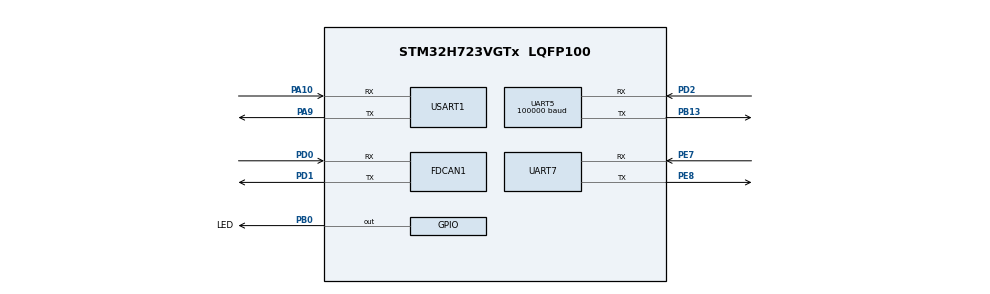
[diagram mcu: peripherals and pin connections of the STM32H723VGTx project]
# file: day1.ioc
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CORTEX_M7.default_mode_Activation=1
Dma.Request0=UART7_TX
Dma.Request1=UART5_RX
Dma.Request2=USART1_TX
Dma.UART5_RX.1.Direction=DMA_PERIPH_TO_MEMORY
Dma.UART5_RX.1.EventEnable=DISABLE
Dma.UART5_RX.1.FIFOMode=DMA_FIFOMODE_DISABLE
Dma.UART5_RX.1.Instance=DMA1_Stream1
Dma.UART5_RX.1.MemDataAlignment=DMA_MDATAALIGN_BYTE
Dma.UART5_RX.1.MemInc=DMA_MINC_ENABLE
Dma.UART5_RX.1.Mode=DMA_NORMAL
Dma.UART5_RX.1.PeriphDataAlignment=DMA_PDATAALIGN_BYTE
Dma.UART5_RX.1.PeriphInc=DMA_PINC_DISABLE
Dma.UART5_RX.1.Polarity=HAL_DMAMUX_REQ_GEN_RISING
Dma.UART5_RX.1.Priority=DMA_PRIORITY_HIGH
Dma.UART5_RX.1.RequestNumber=1
Dma.UART5_RX.1.SignalID=NONE
Dma.UART5_RX.1.SyncEnable=DISABLE
Dma.UART5_RX.1.SyncPolarity=HAL_DMAMUX_SYNC_NO_EVENT
Dma.UART5_RX.1.SyncRequestNumber=1
Dma.UART5_RX.1.SyncSignalID=NONE
Dma.UART7_TX.0.Direction=DMA_MEMORY_TO_PERIPH
Dma.UART7_TX.0.EventEnable=DISABLE
Dma.UART7_TX.0.FIFOMode=DMA_FIFOMODE_DISABLE
Dma.UART7_TX.0.Instance=DMA1_Stream0
Dma.UART7_TX.0.MemDataAlignment=DMA_MDATAALIGN_BYTE
Dma.UART7_TX.0.MemInc=DMA_MINC_ENABLE
Dma.UART7_TX.0.Mode=DMA_NORMAL
Dma.UART7_TX.0.PeriphDataAlignment=DMA_PDATAALIGN_BYTE
Dma.UART7_TX.0.PeriphInc=DMA_PINC_DISABLE
Dma.UART7_TX.0.Polarity=HAL_DMAMUX_REQ_GEN_RISING
Dma.UART7_TX.0.Priority=DMA_PRIORITY_LOW
Dma.UART7_TX.0.RequestNumber=1
Dma.UART7_TX.0.SignalID=NONE
Dma.UART7_TX.0.SyncEnable=DISABLE
Dma.UART7_TX.0.SyncPolarity=HAL_DMAMUX_SYNC_NO_EVENT
Dma.UART7_TX.0.SyncRequestNumber=1
Dma.UART7_TX.0.SyncSignalID=NONE
Dma.USART1_TX.2.Direction=DMA_MEMORY_TO_PERIPH
Dma.USART1_TX.2.EventEnable=DISABLE
Dma.USART1_TX.2.FIFOMode=DMA_FIFOMODE_DISABLE
Dma.USART1_TX.2.Instance=DMA1_Stream2
Dma.USART1_TX.2.MemDataAlignment=DMA_MDATAALIGN_BYTE
Dma.USART1_TX.2.MemInc=DMA_MINC_ENABLE
Dma.USART1_TX.2.Mode=DMA_NORMAL
Dma.USART1_TX.2.PeriphDataAlignment=DMA_PDATAALIGN_BYTE
Dma.USART1_TX.2.PeriphInc=DMA_PINC_DISABLE
Dma.USART1_TX.2.Polarity=HAL_DMAMUX_REQ_GEN_RISING
Dma.USART1_TX.2.Priority=DMA_PRIORITY_LOW
Dma.USART1_TX.2.RequestNumber=1
Dma.USART1_TX.2.SignalID=NONE
Dma.USART1_TX.2.SyncEnable=DISABLE
Dma.USART1_TX.2.SyncPolarity=HAL_DMAMUX_SYNC_NO_EVENT
Dma.USART1_TX.2.SyncRequestNumber=1
Dma.USART1_TX.2.SyncSignalID=NONE
FDCAN1.CalculateBaudRateNominal=999999
FDCAN1.CalculateTimeBitNominal=1000
FDCAN1.CalculateTimeQuantumNominal=16.666666666666668
FDCAN1.DataPrescaler=2
FDCAN1.DataSyncJumpWidth=6
FDCAN1.DataTimeSeg1=17
FDCAN1.DataTimeSeg2=6
FDCAN1.ExtFiltersNbr=4
FDCAN1.Mode=FDCAN_MODE_NORMAL
FDCAN1.NominalPrescaler=2
FDCAN1.NominalSyncJumpWidth=15
FDCAN1.NominalTimeSeg1=44
FDCAN1.NominalTimeSeg2=15
FDCAN1.RxBuffersNbr=8
FDCAN1.RxFifo0ElmtsNbr=8
FDCAN1.RxFifo1ElmtsNbr=8
FDCAN1.StdFiltersNbr=4
FDCAN1.TxBuffersNbr=8
FDCAN1.TxEventsNbr=8
FDCAN1.TxFifoQueueElmtsNbr=8
FREERTOS.Tasks01=defaultTask,24,128,StartDefaultTask,Default,NULL,Dynamic,NULL,NULL
Mcu.Family=STM32H7
Mcu.Name=STM32H723VGTx
Mcu.Package=LQFP100
NVIC.DMA1_Stream0_IRQn=true\:5\:0\:false\:false\:true\:true\:false\:true\:true
NVIC.DMA1_Stream1_IRQn=true\:5\:0\:false\:false\:true\:true\:false\:true\:true
NVIC.DMA1_Stream2_IRQn=true\:5\:0\:false\:false\:true\:true\:false\:true\:true
NVIC.FDCAN1_IT0_IRQn=true\:5\:0\:false\:false\:true\:true\:true\:true\:true
NVIC.FDCAN1_IT1_IRQn=true\:5\:0\:false\:false\:true\:true\:true\:true\:true
NVIC.PriorityGroup=NVIC_PRIORITYGROUP_4
NVIC.TIM6_DAC_IRQn=true\:5\:0\:false\:false\:true\:true\:true\:true\:true
NVIC.UART5_IRQn=true\:5\:0\:false\:false\:true\:true\:true\:true\:true
NVIC.UART7_IRQn=true\:5\:0\:false\:false\:true\:true\:true\:true\:true
NVIC.USART1_IRQn=true\:5\:0\:false\:false\:true\:true\:true\:true\:true
PA10.Mode=Asynchronous
PA10.Signal=USART1_RX
PA13(JTMS/SWDIO).Mode=Serial_Wire
PA13(JTMS/SWDIO).Signal=DEBUG_JTMS-SWDIO
PA14(JTCK/SWCLK).Mode=Serial_Wire
PA14(JTCK/SWCLK).Signal=DEBUG_JTCK-SWCLK
PA9.Mode=Asynchronous
PA9.Signal=USART1_TX
PB0.GPIO_Label=LED
PB0.Signal=GPIO_Output
PB13.Mode=Asynchronous
PB13.Signal=UART5_TX
PD0.Mode=FDCAN_Activate
PD0.Signal=FDCAN1_RX
PD1.Mode=FDCAN_Activate
PD1.Signal=FDCAN1_TX
PD2.Mode=Asynchronous
PD2.Signal=UART5_RX
PE7.Mode=Asynchronous
PE7.Signal=UART7_RX
PE8.Mode=Asynchronous
PE8.Signal=UART7_TX
PH0-OSC_IN.Mode=HSE-External-Oscillator
PH0-OSC_IN.Signal=RCC_OSC_IN
PH1-OSC_OUT.Mode=HSE-External-Oscillator
PH1-OSC_OUT.Signal=RCC_OSC_OUT
ProjectManager.HeapSize=0x200
ProjectManager.StackSize=0x400
ProjectManager.TargetToolchain=CMake
RCC.ADCFreq_Value=48375000
RCC.APB1Freq_Value=120000000
RCC.APB2Freq_Value=120000000
RCC.APB3Freq_Value=120000000
RCC.APB4Freq_Value=120000000
RCC.CortexFreq_Value=480000000
RCC.D1PPRE=RCC_APB3_DIV2
RCC.D2PPRE1=RCC_APB1_DIV2
RCC.D2PPRE2=RCC_APB2_DIV2
RCC.D3PPRE=RCC_APB4_DIV2
RCC.DIVM1=2
RCC.DIVN1=40
RCC.DIVP1=1
RCC.DIVQ1=4
RCC.HCLKFreq_Value=240000000
RCC.HPRE=RCC_HCLK_DIV2
RCC.HSE_VALUE=24000000
RCC.PLL2FRACN=0
RCC.PLL3FRACN=0
RCC.PLLFRACN=0
RCC.PLLSourceVirtual=RCC_PLLSOURCE_HSE
RCC.SYSCLKFreq_VALUE=480000000
RCC.SYSCLKSource=RCC_SYSCLKSOURCE_PLLCLK
RCC.USBFreq_Value=120000000
TIM6.AutoReloadPreload=TIM_AUTORELOAD_PRELOAD_ENABLE
TIM6.Period=4999
TIM6.Prescaler=119
UART5.BaudRate=100000
UART5.Parity=PARITY_EVEN
UART5.WordLength=WORDLENGTH_9B
USART1.VirtualMode-Asynchronous=VM_ASYNC
VP_FREERTOS_VS_CMSIS_V2.Mode=CMSIS_V2
VP_MEMORYMAP_VS_MEMORYMAP.Mode=CurAppReg
VP_TIM6_VS_ClockSourceINT.Mode=Enable_Timer
board=custom

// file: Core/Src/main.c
/* USER CODE BEGIN Header */
/**
  ******************************************************************************
  * @file           : main.c
  * @brief          : Main program body
  ******************************************************************************
  * @attention
  *
  * Copyright (c) 2026 STMicroelectronics.
  * All rights reserved.
  *
  * This software is licensed under terms that can be found in the LICENSE file
  * in the root directory of this software component.
  * If no LICENSE file comes with this software, it is provided AS-IS.
  *
  ******************************************************************************
  */
/* USER CODE END Header */
#include "main.h"
#include "FreeRTOS.h"
#include "cmsis_os2.h"
#include "dma.h"
#include "fdcan.h"
#include "tim.h"
#include "usart.h"
#include "gpio.h"

/* USER CODE BEGIN Includes */
#include <stdio.h>
/* USER CODE END Includes */

void SystemClock_Config(void);
static void MPU_Config(void);
void MX_FREERTOS_Init(void);

/* USER CODE BEGIN 0 */

/* __io_putchar: printf() 底层输出，通过 UART7 发送字符（USART1 留给 VOFA 绘图） */
int __io_putchar(int ch)
{
  if (ch == '\n') {
    uint8_t cr = '\r';
    HAL_UART_Transmit(&huart7, &cr, 1, HAL_MAX_DELAY);
  }
  uint8_t c = (uint8_t)ch;
  HAL_UART_Transmit(&huart7, &c, 1, HAL_MAX_DELAY);
  return ch;
}
/* USER CODE END 0 */

int main(void)
{

  /* MPU Configuration--------------------------------------------------------*/
  MPU_Config();

  /* MCU Configuration--------------------------------------------------------*/

  /* Reset of all peripherals, Initializes the Flash interface and the Systick. */
  HAL_Init();

  /* Configure the system clock */
  SystemClock_Config();

  /* Initialize all configured peripherals */
  MX_GPIO_Init();
  MX_DMA_Init();
  MX_FDCAN1_Init();
  MX_USART1_UART_Init();
  MX_UART7_Init();
  MX_UART5_Init();
  MX_TIM6_Init();

  /* Init scheduler */
  osKernelInitialize();  /* Call init function for freertos objects (in cmsis_os2.c) */
  MX_FREERTOS_Init();

  /* Start scheduler */
  osKernelStart();

  /* We should never get here as control is now taken by the scheduler */

  /* Infinite loop */
  while (1)
  {

  }
}

void SystemClock_Config(void)
{
  RCC_OscInitTypeDef RCC_OscInitStruct = {0};
  RCC_ClkInitTypeDef RCC_ClkInitStruct = {0};

  /** Supply configuration update enable
  */
  HAL_PWREx_ConfigSupply(PWR_LDO_SUPPLY);

  /** Configure the main internal regulator output voltage
  */
  __HAL_PWR_VOLTAGESCALING_CONFIG(PWR_REGULATOR_VOLTAGE_SCALE0);

  while(!__HAL_PWR_GET_FLAG(PWR_FLAG_VOSRDY)) {}

  /** Initializes the RCC Oscillators according to the specified parameters
  * in the RCC_OscInitTypeDef structure.
  */
  RCC_OscInitStruct.OscillatorType = RCC_OSCILLATORTYPE_HSE;
  RCC_OscInitStruct.HSEState = RCC_HSE_ON;
  RCC_OscInitStruct.PLL.PLLState = RCC_PLL_ON;
  RCC_OscInitStruct.PLL.PLLSource = RCC_PLLSOURCE_HSE;
  RCC_OscInitStruct.PLL.PLLM = 2;
  RCC_OscInitStruct.PLL.PLLN = 40;
  RCC_OscInitStruct.PLL.PLLP = 1;
  RCC_OscInitStruct.PLL.PLLQ = 4;
  RCC_OscInitStruct.PLL.PLLR = 2;
  RCC_OscInitStruct.PLL.PLLRGE = RCC_PLL1VCIRANGE_3;
  RCC_OscInitStruct.PLL.PLLVCOSEL = RCC_PLL1VCOWIDE;
  RCC_OscInitStruct.PLL.PLLFRACN = 0;
  if (HAL_RCC_OscConfig(&RCC_OscInitStruct) != HAL_OK)
  {
    Error_Handler();
  }

  /** Initializes the CPU, AHB and APB buses clocks
  */
  RCC_ClkInitStruct.ClockType = RCC_CLOCKTYPE_HCLK|RCC_CLOCKTYPE_SYSCLK
                              |RCC_CLOCKTYPE_PCLK1|RCC_CLOCKTYPE_PCLK2
                              |RCC_CLOCKTYPE_D3PCLK1|RCC_CLOCKTYPE_D1PCLK1;
  RCC_ClkInitStruct.SYSCLKSource = RCC_SYSCLKSOURCE_PLLCLK;
  RCC_ClkInitStruct.SYSCLKDivider = RCC_SYSCLK_DIV1;
  RCC_ClkInitStruct.AHBCLKDivider = RCC_HCLK_DIV2;
  RCC_ClkInitStruct.APB3CLKDivider = RCC_APB3_DIV2;
  RCC_ClkInitStruct.APB1CLKDivider = RCC_APB1_DIV2;
  RCC_ClkInitStruct.APB2CLKDivider = RCC_APB2_DIV2;
  RCC_ClkInitStruct.APB4CLKDivider = RCC_APB4_DIV2;

  if (HAL_RCC_ClockConfig(&RCC_ClkInitStruct, FLASH_LATENCY_3) != HAL_OK)
  {
    Error_Handler();
  }
}

 /* MPU Configuration */

void MPU_Config(void)
{
  MPU_Region_InitTypeDef MPU_InitStruct = {0};

  /* Disables the MPU */
  HAL_MPU_Disable();

  /** Initializes and configures the Region and the memory to be protected
  */
  MPU_InitStruct.Enable = MPU_REGION_ENABLE;
  MPU_InitStruct.Number = MPU_REGION_NUMBER0;
  MPU_InitStruct.BaseAddress = 0x0;
  MPU_InitStruct.Size = MPU_REGION_SIZE_4GB;
  MPU_InitStruct.SubRegionDisable = 0x87;
  MPU_InitStruct.TypeExtField = MPU_TEX_LEVEL0;
  MPU_InitStruct.AccessPermission = MPU_REGION_NO_ACCESS;
  MPU_InitStruct.DisableExec = MPU_INSTRUCTION_ACCESS_DISABLE;
  MPU_InitStruct.IsShareable = MPU_ACCESS_SHAREABLE;
  MPU_InitStruct.IsCacheable = MPU_ACCESS_NOT_CACHEABLE;
  MPU_InitStruct.IsBufferable = MPU_ACCESS_NOT_BUFFERABLE;

  HAL_MPU_ConfigRegion(&MPU_InitStruct);
  /* Enables the MPU */
  HAL_MPU_Enable(MPU_PRIVILEGED_DEFAULT);

}

void Error_Handler(void)
{
  __disable_irq();
  while (1)
  {
  }
}
